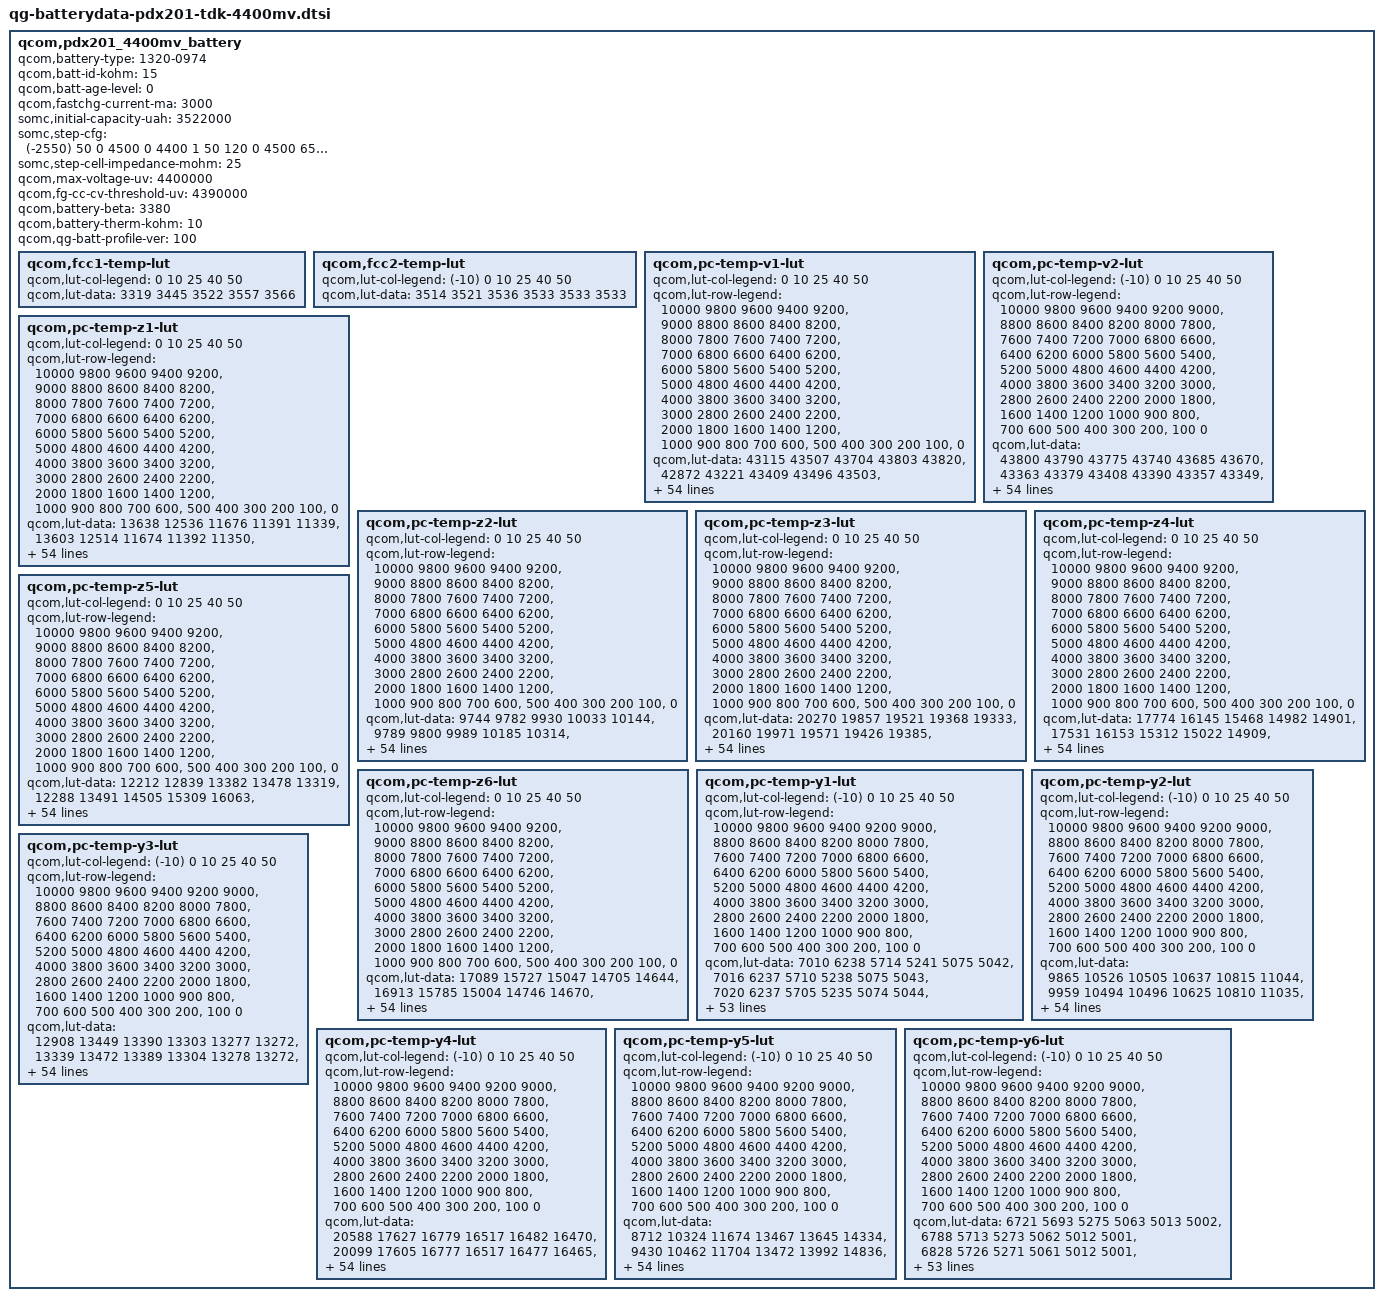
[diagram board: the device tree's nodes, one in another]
// SPDX-License-Identifier: GPL-2.0-only
/*
 * Copyright (c) 2019, The Linux Foundation. All rights reserved.
 */

qcom,pdx201_4400mv_battery {
	/* Added or Modified by SOMC */
	qcom,battery-type = "1320-0974";
	qcom,batt-id-kohm = <15>;
	qcom,batt-age-level = <0>;
	qcom,fastchg-current-ma = <3000>;
	somc,initial-capacity-uah = <3522000>;
	somc,step-cfg = <
		(-2550) 50    0 4500    0 4400 1
		   50  120    0 4500  650 4400 2
		  120  200    0 4100 2050 4400 3
		  120  200 4100 4200 1700 4400 3
		  120  200 4200 4300 1350 4400 3
		  120  200 4300 4500 1000 4400 3
		  200  450    0 4150 3000 4400 3
		  200  450 4150 4200 2550 4400 3
		  200  450 4200 4300 1700 4400 3
		  200  450 4300 4500 1000 4400 3
		  450  550    0 4500 1000 4200 4
		  550 2550    0 4500    0 4200 5
	>;
	somc,step-cell-impedance-mohm = <25>;

	/* Prepared by Qualcomm */
	/* 4176676_SoMC_Amuro2_3564mAh_averaged_MasterSlave_Sept16th2019 */
	qcom,max-voltage-uv = <4400000>;
	qcom,fg-cc-cv-threshold-uv = <4390000>;
	/* qcom,fastchg-current-ma = <1500>; */
	/* qcom,batt-id-kohm = <330>; */
	qcom,battery-beta = <3380>;
	qcom,battery-therm-kohm = <10>;
	/* qcom,battery-type = "4176676_SoMC_Amuro2_3564mAh_averaged_MasterSlave_Sept16th2019"; */
	qcom,qg-batt-profile-ver = <100>;

	qcom,fcc1-temp-lut {
		qcom,lut-col-legend = <0 10 25 40 50>;
		qcom,lut-data = <3319 3445 3522 3557 3566>;
	};

	qcom,fcc2-temp-lut {
		qcom,lut-col-legend = <(-10) 0 10 25 40 50>;
		qcom,lut-data = <3514 3521 3536 3533 3533 3533>;
	};

	qcom,pc-temp-v1-lut {
		qcom,lut-col-legend = <0 10 25 40 50>;
		qcom,lut-row-legend = <10000 9800 9600 9400 9200>,
			<9000 8800 8600 8400 8200>,
			<8000 7800 7600 7400 7200>,
			<7000 6800 6600 6400 6200>,
			<6000 5800 5600 5400 5200>,
			<5000 4800 4600 4400 4200>,
			<4000 3800 3600 3400 3200>,
			<3000 2800 2600 2400 2200>,
			<2000 1800 1600 1400 1200>,
			<1000 900 800 700 600>,
			<500 400 300 200 100>,
			<0>;
		qcom,lut-data = <43115 43507 43704 43803 43820>,
			<42872 43221 43409 43496 43503>,
			<42638 42969 43135 43212 43218>,
			<42413 42735 42882 42952 42956>,
			<42195 42504 42643 42714 42718>,
			<41984 42279 42407 42480 42488>,
			<41780 42059 42176 42246 42258>,
			<41585 41845 41951 42014 42031>,
			<41412 41638 41731 41788 41806>,
			<41248 41443 41516 41567 41580>,
			<41056 41269 41314 41350 41359>,
			<40806 41086 41131 41138 41144>,
			<40539 40857 40938 40930 40933>,
			<40297 40590 40702 40722 40728>,
			<40059 40341 40443 40506 40526>,
			<39867 40106 40226 40306 40333>,
			<39744 39902 40044 40129 40151>,
			<39648 39769 39885 39964 39978>,
			<39548 39678 39751 39808 39813>,
			<39436 39581 39630 39662 39660>,
			<39321 39455 39491 39504 39500>,
			<39205 39310 39329 39320 39315>,
			<39086 39145 39153 39125 39120>,
			<38970 38939 38945 38942 38940>,
			<38858 38753 38718 38763 38771>,
			<38748 38619 38571 38615 38624>,
			<38647 38509 38489 38508 38507>,
			<38550 38428 38423 38418 38406>,
			<38463 38369 38351 38331 38315>,
			<38395 38322 38281 38246 38231>,
			<38340 38278 38219 38172 38157>,
			<38295 38239 38163 38109 38088>,
			<38263 38202 38114 38055 38026>,
			<38237 38168 38073 38007 37974>,
			<38214 38137 38039 37967 37931>,
			<38192 38108 38005 37927 37886>,
			<38171 38083 37973 37884 37832>,
			<38137 38050 37937 37838 37771>,
			<38083 37995 37882 37776 37703>,
			<38012 37915 37801 37696 37628>,
			<37922 37825 37708 37604 37541>,
			<37804 37719 37604 37499 37433>,
			<37668 37593 37481 37377 37305>,
			<37516 37439 37325 37220 37148>,
			<37381 37290 37178 37074 37006>,
			<37288 37194 37081 36978 36915>,
			<37267 37172 37055 36955 36892>,
			<37247 37151 37038 36941 36876>,
			<37217 37131 37026 36924 36859>,
			<37145 37087 36979 36873 36800>,
			<36905 36852 36738 36612 36519>,
			<36458 36417 36309 36184 36091>,
			<35883 35850 35747 35624 35532>,
			<35120 35085 34984 34864 34773>,
			<33902 33885 33806 33695 33606>,
			<30000 30000 30000 30000 30000>;
	};

	qcom,pc-temp-v2-lut {
		qcom,lut-col-legend = <(-10) 0 10 25 40 50>;
		qcom,lut-row-legend = <10000 9800 9600 9400 9200 9000>,
			<8800 8600 8400 8200 8000 7800>,
			<7600 7400 7200 7000 6800 6600>,
			<6400 6200 6000 5800 5600 5400>,
			<5200 5000 4800 4600 4400 4200>,
			<4000 3800 3600 3400 3200 3000>,
			<2800 2600 2400 2200 2000 1800>,
			<1600 1400 1200 1000 900 800>,
			<700 600 500 400 300 200>,
			<100 0>;
		qcom,lut-data = <43800 43790 43775 43740 43685 43670>,
			<43363 43379 43408 43390 43357 43349>,
			<42985 43018 43080 43073 43055 43053>,
			<42679 42716 42797 42797 42786 42786>,
			<42438 42464 42554 42557 42546 42546>,
			<42202 42229 42324 42328 42314 42314>,
			<41913 41999 42096 42097 42083 42083>,
			<41625 41778 41875 41871 41856 41855>,
			<41448 41554 41655 41647 41632 41632>,
			<41353 41318 41432 41422 41411 41411>,
			<41247 41111 41224 41209 41195 41194>,
			<41055 40969 41055 41022 40987 40982>,
			<40781 40850 40897 40845 40783 40775>,
			<40465 40656 40684 40630 40572 40573>,
			<40028 40279 40375 40349 40344 40374>,
			<39660 39908 40079 40096 40134 40183>,
			<39512 39690 39868 39931 39972 40007>,
			<39420 39521 39690 39800 39830 39840>,
			<39300 39362 39519 39660 39681 39677>,
			<39129 39212 39359 39517 39528 39524>,
			<38923 39068 39200 39359 39361 39360>,
			<38650 38917 39029 39153 39154 39154>,
			<38310 38766 38855 38915 38921 38922>,
			<38130 38630 38702 38728 38736 38737>,
			<38075 38518 38569 38588 38592 38593>,
			<38037 38405 38451 38469 38469 38471>,
			<37994 38247 38347 38363 38362 38362>,
			<37952 38055 38253 38268 38267 38267>,
			<37910 37943 38167 38182 38181 38178>,
			<37868 37904 38090 38105 38102 38096>,
			<37826 37874 38017 38035 38031 38023>,
			<37784 37836 37937 37969 37964 37956>,
			<37744 37793 37859 37908 37904 37898>,
			<37703 37753 37803 37849 37844 37836>,
			<37664 37720 37769 37794 37787 37773>,
			<37623 37687 37736 37739 37725 37703>,
			<37577 37650 37696 37680 37643 37608>,
			<37526 37608 37651 37618 37542 37488>,
			<37468 37558 37597 37552 37451 37386>,
			<37398 37493 37530 37481 37381 37312>,
			<37319 37415 37451 37404 37311 37241>,
			<37239 37324 37356 37311 37221 37151>,
			<37158 37211 37241 37199 37110 37041>,
			<37081 37090 37103 37059 36968 36903>,
			<37007 36970 36972 36929 36846 36786>,
			<36932 36885 36899 36873 36809 36751>,
			<36887 36849 36881 36860 36797 36737>,
			<36825 36811 36858 36841 36778 36718>,
			<36761 36764 36826 36810 36743 36685>,
			<36644 36672 36748 36737 36646 36575>,
			<36395 36444 36504 36478 36345 36245>,
			<35973 36001 36024 36018 35868 35761>,
			<35363 35399 35407 35416 35249 35139>,
			<34484 34553 34572 34623 34413 34285>,
			<33079 33226 33373 33430 33159 33009>,
			<29553 29529 29520 29703 29771 29781>;
	};

	qcom,pc-temp-z1-lut {
		qcom,lut-col-legend = <0 10 25 40 50>;
		qcom,lut-row-legend = <10000 9800 9600 9400 9200>,
			<9000 8800 8600 8400 8200>,
			<8000 7800 7600 7400 7200>,
			<7000 6800 6600 6400 6200>,
			<6000 5800 5600 5400 5200>,
			<5000 4800 4600 4400 4200>,
			<4000 3800 3600 3400 3200>,
			<3000 2800 2600 2400 2200>,
			<2000 1800 1600 1400 1200>,
			<1000 900 800 700 600>,
			<500 400 300 200 100>,
			<0>;
		qcom,lut-data = <13638 12536 11676 11391 11339>,
			<13603 12514 11674 11392 11350>,
			<13593 12501 11673 11398 11352>,
			<13596 12492 11670 11399 11354>,
			<13600 12487 11667 11399 11356>,
			<13601 12483 11665 11399 11357>,
			<13603 12481 11664 11399 11357>,
			<13604 12483 11664 11399 11356>,
			<13607 12486 11665 11399 11356>,
			<13611 12487 11667 11400 11356>,
			<13607 12487 11669 11401 11357>,
			<13577 12486 11673 11403 11358>,
			<13541 12476 11676 11406 11358>,
			<13526 12452 11669 11405 11359>,
			<13516 12437 11657 11399 11359>,
			<13510 12432 11653 11395 11360>,
			<13503 12429 11653 11397 11361>,
			<13488 12432 11655 11401 11362>,
			<13485 12448 11660 11403 11363>,
			<13503 12462 11669 11404 11364>,
			<13525 12470 11675 11405 11365>,
			<13532 12476 11678 11406 11365>,
			<13529 12481 11681 11407 11366>,
			<13526 12487 11684 11408 11367>,
			<13528 12492 11687 11410 11369>,
			<13531 12494 11691 11413 11370>,
			<13535 12499 11695 11416 11372>,
			<13537 12503 11700 11419 11373>,
			<13540 12508 11704 11421 11375>,
			<13546 12513 11707 11423 11378>,
			<13559 12518 11710 11424 11380>,
			<13571 12525 11714 11427 11381>,
			<13574 12528 11718 11430 11383>,
			<13576 12530 11721 11431 11384>,
			<13579 12532 11724 11433 11385>,
			<13584 12536 11727 11434 11386>,
			<13591 12546 11730 11435 11387>,
			<13596 12553 11734 11436 11388>,
			<13603 12556 11736 11437 11389>,
			<13608 12557 11739 11438 11389>,
			<13610 12560 11740 11439 11390>,
			<13614 12566 11742 11441 11390>,
			<13601 12569 11743 11441 11391>,
			<13571 12565 11746 11441 11390>,
			<13550 12574 11750 11441 11391>,
			<13581 12571 11751 11442 11390>,
			<13550 12570 11749 11442 11391>,
			<13554 12568 11748 11442 11391>,
			<13553 12568 11745 11441 11391>,
			<13539 12573 11752 11442 11391>,
			<13560 12584 11754 11445 11393>,
			<13582 12588 11764 11448 11395>,
			<13591 12628 11778 11456 11402>,
			<13647 12665 11807 11469 11411>,
			<13647 12665 11807 11469 11411>,
			<13647 12665 11807 11469 11411>;
	};

	qcom,pc-temp-z2-lut {
		qcom,lut-col-legend = <0 10 25 40 50>;
		qcom,lut-row-legend = <10000 9800 9600 9400 9200>,
			<9000 8800 8600 8400 8200>,
			<8000 7800 7600 7400 7200>,
			<7000 6800 6600 6400 6200>,
			<6000 5800 5600 5400 5200>,
			<5000 4800 4600 4400 4200>,
			<4000 3800 3600 3400 3200>,
			<3000 2800 2600 2400 2200>,
			<2000 1800 1600 1400 1200>,
			<1000 900 800 700 600>,
			<500 400 300 200 100>,
			<0>;
		qcom,lut-data = <9744 9782 9930 10033 10144>,
			<9789 9800 9989 10185 10314>,
			<9805 9799 10014 10345 10561>,
			<9804 9797 10008 10367 10620>,
			<9802 9800 9998 10332 10602>,
			<9803 9815 9998 10311 10573>,
			<9807 9827 10007 10332 10479>,
			<9811 9831 10015 10364 10341>,
			<9815 9833 10018 10342 10309>,
			<9819 9835 10021 10219 10324>,
			<9819 9835 10025 10143 10342>,
			<9803 9836 10029 10142 10360>,
			<9785 9840 10035 10144 10379>,
			<9783 9848 10061 10156 10390>,
			<9791 9853 10099 10197 10392>,
			<9799 9856 10109 10222 10393>,
			<9806 9860 10095 10221 10405>,
			<9813 9873 10083 10219 10422>,
			<9815 9908 10106 10223 10424>,
			<9809 9942 10156 10245 10424>,
			<9801 9962 10173 10280 10426>,
			<9801 9980 10167 10371 10462>,
			<9808 9998 10162 10476 10528>,
			<9817 10021 10164 10467 10551>,
			<9825 10034 10171 10338 10552>,
			<9833 10034 10180 10257 10543>,
			<9841 10031 10192 10302 10502>,
			<9849 10028 10205 10367 10434>,
			<9856 10019 10218 10382 10381>,
			<9860 10012 10232 10381 10333>,
			<9863 10012 10236 10375 10308>,
			<9865 10015 10221 10365 10309>,
			<9867 10020 10205 10355 10317>,
			<9869 10025 10208 10363 10332>,
			<9870 10032 10222 10411 10372>,
			<9873 10038 10235 10454 10421>,
			<9878 10043 10244 10474 10480>,
			<9884 10049 10254 10492 10539>,
			<9897 10056 10269 10521 10559>,
			<9912 10065 10289 10571 10567>,
			<9926 10073 10303 10599 10574>,
			<9941 10079 10308 10543 10593>,
			<9964 10089 10313 10488 10612>,
			<10012 10110 10324 10510 10603>,
			<10241 10239 10385 10559 10625>,
			<10244 10263 10419 10555 10681>,
			<10231 10259 10407 10532 10658>,
			<10228 10265 10397 10540 10662>,
			<10234 10263 10399 10548 10671>,
			<10261 10299 10423 10642 10774>,
			<10277 10309 10486 10616 10526>,
			<10223 10256 10443 10531 10446>,
			<10136 10215 10407 10464 10375>,
			<10060 10205 10288 10383 10328>,
			<10060 10205 10288 10383 10328>,
			<10060 10205 10288 10383 10328>;
	};

	qcom,pc-temp-z3-lut {
		qcom,lut-col-legend = <0 10 25 40 50>;
		qcom,lut-row-legend = <10000 9800 9600 9400 9200>,
			<9000 8800 8600 8400 8200>,
			<8000 7800 7600 7400 7200>,
			<7000 6800 6600 6400 6200>,
			<6000 5800 5600 5400 5200>,
			<5000 4800 4600 4400 4200>,
			<4000 3800 3600 3400 3200>,
			<3000 2800 2600 2400 2200>,
			<2000 1800 1600 1400 1200>,
			<1000 900 800 700 600>,
			<500 400 300 200 100>,
			<0>;
		qcom,lut-data = <20270 19857 19521 19368 19333>,
			<20160 19971 19571 19426 19385>,
			<20084 19966 19594 19448 19409>,
			<20030 19954 19595 19449 19412>,
			<19992 19939 19595 19445 19410>,
			<19972 19913 19591 19440 19406>,
			<19959 19886 19572 19435 19394>,
			<19950 19865 19552 19428 19376>,
			<19945 19846 19537 19417 19368>,
			<19941 19827 19524 19397 19366>,
			<19940 19810 19520 19385 19363>,
			<19949 19794 19518 19385 19357>,
			<19960 19779 19517 19385 19349>,
			<19963 19759 19506 19382 19345>,
			<19957 19749 19489 19370 19344>,
			<19946 19740 19479 19363 19342>,
			<19922 19726 19460 19363 19336>,
			<19885 19705 19445 19363 19329>,
			<19871 19667 19438 19362 19327>,
			<19898 19647 19430 19355 19327>,
			<19939 19652 19435 19351 19328>,
			<19966 19663 19466 19368 19336>,
			<19986 19683 19495 19393 19352>,
			<20001 19734 19505 19393 19352>,
			<20011 19772 19512 19371 19332>,
			<20019 19771 19512 19357 19318>,
			<20025 19765 19497 19361 19335>,
			<20029 19758 19481 19370 19365>,
			<20032 19744 19485 19383 19371>,
			<20032 19728 19499 19407 19370>,
			<20024 19717 19509 19420 19368>,
			<20013 19708 19515 19417 19367>,
			<20001 19704 19519 19409 19365>,
			<19985 19705 19518 19404 19362>,
			<19971 19705 19511 19399 19355>,
			<19959 19705 19505 19395 19351>,
			<19949 19702 19501 19390 19352>,
			<19938 19699 19497 19386 19353>,
			<19929 19694 19493 19384 19353>,
			<19918 19688 19489 19384 19348>,
			<19904 19681 19484 19382 19345>,
			<19886 19672 19478 19375 19346>,
			<19863 19659 19471 19365 19346>,
			<19828 19641 19464 19361 19346>,
			<19688 19580 19442 19356 19338>,
			<19681 19568 19434 19355 19331>,
			<19671 19557 19435 19353 19329>,
			<19663 19554 19432 19345 19327>,
			<19662 19551 19416 19344 19324>,
			<19655 19537 19415 19334 19320>,
			<19643 19542 19405 19343 19344>,
			<19641 19535 19403 19348 19349>,
			<19635 19530 19405 19356 19353>,
			<19571 19481 19391 19359 19357>,
			<19571 19481 19391 19359 19357>,
			<19571 19481 19391 19359 19357>;
	};

	qcom,pc-temp-z4-lut {
		qcom,lut-col-legend = <0 10 25 40 50>;
		qcom,lut-row-legend = <10000 9800 9600 9400 9200>,
			<9000 8800 8600 8400 8200>,
			<8000 7800 7600 7400 7200>,
			<7000 6800 6600 6400 6200>,
			<6000 5800 5600 5400 5200>,
			<5000 4800 4600 4400 4200>,
			<4000 3800 3600 3400 3200>,
			<3000 2800 2600 2400 2200>,
			<2000 1800 1600 1400 1200>,
			<1000 900 800 700 600>,
			<500 400 300 200 100>,
			<0>;
		qcom,lut-data = <17774 16145 15468 14982 14901>,
			<17531 16153 15312 15022 14909>,
			<17261 15934 15185 14962 14875>,
			<16942 15611 15084 14913 14840>,
			<16635 15427 15002 14872 14803>,
			<16405 15307 14943 14840 14782>,
			<16217 15215 14895 14815 14782>,
			<16060 15144 14865 14797 14783>,
			<15930 15087 14853 14795 14781>,
			<15820 15037 14844 14796 14772>,
			<15721 14986 14833 14796 14761>,
			<15632 14951 14818 14792 14755>,
			<15553 14938 14807 14783 14749>,
			<15481 14930 14804 14775 14741>,
			<15415 14924 14803 14767 14730>,
			<15359 14913 14799 14757 14719>,
			<15317 14902 14791 14737 14711>,
			<15282 14895 14786 14715 14704>,
			<15241 14891 14783 14705 14696>,
			<15181 14886 14774 14700 14684>,
			<15120 14876 14764 14698 14677>,
			<15079 14865 14747 14706 14691>,
			<15046 14865 14735 14726 14722>,
			<15027 14886 14775 14761 14760>,
			<15024 14911 14867 14834 14819>,
			<15023 14933 14900 14875 14852>,
			<15023 14956 14894 14860 14827>,
			<15030 14964 14882 14831 14779>,
			<15040 14959 14862 14799 14752>,
			<15045 14952 14831 14757 14736>,
			<15048 14944 14806 14729 14723>,
			<15050 14935 14787 14720 14709>,
			<15049 14925 14773 14714 14698>,
			<15044 14912 14768 14709 14693>,
			<15039 14900 14766 14704 14689>,
			<15031 14894 14765 14702 14687>,
			<15023 14890 14767 14708 14698>,
			<15014 14888 14770 14720 14716>,
			<15004 14893 14778 14729 14720>,
			<14997 14902 14795 14737 14721>,
			<14996 14905 14803 14741 14721>,
			<14995 14899 14796 14739 14713>,
			<14987 14891 14790 14738 14705>,
			<14950 14875 14789 14743 14709>,
			<14868 14815 14768 14735 14710>,
			<14858 14799 14744 14719 14703>,
			<14855 14795 14731 14709 14691>,
			<14847 14785 14726 14696 14673>,
			<14830 14778 14724 14680 14656>,
			<14826 14776 14724 14693 14665>,
			<14841 14788 14754 14709 14664>,
			<14858 14798 14758 14706 14661>,
			<14865 14799 14752 14696 14656>,
			<14920 14830 14761 14689 14651>,
			<14920 14830 14761 14689 14651>,
			<14920 14830 14761 14689 14651>;
	};

	qcom,pc-temp-z5-lut {
		qcom,lut-col-legend = <0 10 25 40 50>;
		qcom,lut-row-legend = <10000 9800 9600 9400 9200>,
			<9000 8800 8600 8400 8200>,
			<8000 7800 7600 7400 7200>,
			<7000 6800 6600 6400 6200>,
			<6000 5800 5600 5400 5200>,
			<5000 4800 4600 4400 4200>,
			<4000 3800 3600 3400 3200>,
			<3000 2800 2600 2400 2200>,
			<2000 1800 1600 1400 1200>,
			<1000 900 800 700 600>,
			<500 400 300 200 100>,
			<0>;
		qcom,lut-data = <12212 12839 13382 13478 13319>,
			<12288 13491 14505 15309 16063>,
			<12396 13827 15287 16459 17601>,
			<12566 14071 15774 16701 18276>,
			<12748 14279 16142 16721 18737>,
			<12882 14456 16415 16778 18954>,
			<12994 14624 16651 17133 18202>,
			<13086 14780 16755 17580 16836>,
			<13149 14942 16622 17409 16524>,
			<13202 15195 16409 16309 16718>,
			<13282 15674 16442 15644 16854>,
			<13465 16095 16965 15833 16639>,
			<13664 16331 17365 16123 16269>,
			<13767 16647 17061 16086 16254>,
			<13852 16805 16538 15656 16706>,
			<13866 16818 16372 15402 17036>,
			<13748 16751 16061 16240 16953>,
			<13566 16454 15691 17494 16800>,
			<13510 15842 15454 17731 16863>,
			<14112 15504 15278 17561 17627>,
			<15180 16044 16150 17511 18887>,
			<16276 17434 21145 23134 22353>,
			<17587 20253 25668 31425 26987>,
			<18974 28450 26495 31127 26841>,
			<20340 34642 26956 22317 19534>,
			<21727 33528 26771 16323 14305>,
			<22963 30211 22446 15602 14942>,
			<24248 27363 18175 15220 16287>,
			<25257 24760 18075 15724 17193>,
			<25384 22667 18697 18648 17768>,
			<24964 21742 19524 21357 18479>,
			<24382 21127 21382 22640 19915>,
			<23668 20908 23305 23673 21723>,
			<22701 21354 24074 24957 23073>,
			<22083 22091 24557 26586 24329>,
			<21805 22554 24705 27384 24959>,
			<21624 22916 24497 26376 24639>,
			<21665 23096 24075 24462 23841>,
			<22258 23045 23351 22956 22659>,
			<22827 22889 22014 21582 20402>,
			<22856 22624 20913 20237 19067>,
			<22759 21923 20274 18876 19090>,
			<23105 21485 19695 17654 19118>,
			<24125 21317 18941 16539 18333>,
			<24632 23018 19280 16681 16856>,
			<24827 23491 20029 17280 16399>,
			<23314 22244 20498 17378 16692>,
			<22782 22442 20481 17230 17704>,
			<23778 22553 18760 18126 19333>,
			<24028 21583 19227 16420 17540>,
			<22492 21657 16416 15154 18371>,
			<19474 19030 15759 15249 19007>,
			<17856 17760 15636 15906 20142>,
			<14403 14565 14559 16398 21340>,
			<14403 14565 14559 16398 21340>,
			<14403 14565 14559 16398 21340>;
	};

	qcom,pc-temp-z6-lut {
		qcom,lut-col-legend = <0 10 25 40 50>;
		qcom,lut-row-legend = <10000 9800 9600 9400 9200>,
			<9000 8800 8600 8400 8200>,
			<8000 7800 7600 7400 7200>,
			<7000 6800 6600 6400 6200>,
			<6000 5800 5600 5400 5200>,
			<5000 4800 4600 4400 4200>,
			<4000 3800 3600 3400 3200>,
			<3000 2800 2600 2400 2200>,
			<2000 1800 1600 1400 1200>,
			<1000 900 800 700 600>,
			<500 400 300 200 100>,
			<0>;
		qcom,lut-data = <17089 15727 15047 14705 14644>,
			<16913 15785 15004 14746 14670>,
			<16743 15689 14964 14737 14670>,
			<16566 15533 14924 14725 14667>,
			<16408 15437 14887 14704 14651>,
			<16293 15369 14855 14686 14636>,
			<16201 15314 14825 14673 14626>,
			<16126 15270 14803 14662 14619>,
			<16065 15234 14789 14652 14613>,
			<16012 15202 14779 14643 14607>,
			<15964 15174 14771 14636 14601>,
			<15921 15150 14766 14633 14595>,
			<15881 15130 14760 14631 14589>,
			<15843 15113 14751 14626 14583>,
			<15804 15099 14740 14615 14577>,
			<15768 15087 14730 14605 14571>,
			<15734 15076 14718 14596 14564>,
			<15701 15061 14707 14588 14558>,
			<15686 15043 14700 14581 14552>,
			<15681 15034 14694 14575 14547>,
			<15678 15035 14693 14573 14544>,
			<15677 15037 14700 14584 14554>,
			<15678 15045 14713 14605 14576>,
			<15679 15081 14740 14624 14593>,
			<15682 15115 14781 14644 14608>,
			<15688 15125 14795 14653 14616>,
			<15694 15132 14785 14649 14614>,
			<15701 15134 14773 14642 14609>,
			<15707 15126 14766 14636 14603>,
			<15708 15114 14761 14631 14595>,
			<15708 15106 14756 14626 14588>,
			<15706 15099 14752 14619 14581>,
			<15701 15094 14748 14613 14576>,
			<15691 15089 14744 14607 14570>,
			<15682 15085 14740 14602 14565>,
			<15675 15083 14738 14599 14562>,
			<15668 15082 14737 14600 14567>,
			<15662 15081 14736 14602 14574>,
			<15655 15082 14737 14605 14576>,
			<15649 15083 14742 14608 14574>,
			<15643 15083 14744 14609 14572>,
			<15637 15078 14739 14604 14569>,
			<15622 15070 14733 14599 14566>,
			<15585 15056 14729 14599 14568>,
			<15482 15002 14709 14593 14564>,
			<15473 14991 14694 14585 14557>,
			<15465 14982 14689 14580 14551>,
			<15453 14974 14685 14570 14542>,
			<15448 14969 14675 14562 14533>,
			<15448 14964 14676 14562 14534>,
			<15458 14977 14684 14575 14547>,
			<15478 14984 14688 14577 14550>,
			<15497 14994 14689 14579 14551>,
			<15521 15002 14693 14580 14553>,
			<15521 15002 14693 14580 14553>,
			<15521 15002 14693 14580 14553>;
	};

	qcom,pc-temp-y1-lut {
		qcom,lut-col-legend = <(-10) 0 10 25 40 50>;
		qcom,lut-row-legend = <10000 9800 9600 9400 9200 9000>,
			<8800 8600 8400 8200 8000 7800>,
			<7600 7400 7200 7000 6800 6600>,
			<6400 6200 6000 5800 5600 5400>,
			<5200 5000 4800 4600 4400 4200>,
			<4000 3800 3600 3400 3200 3000>,
			<2800 2600 2400 2200 2000 1800>,
			<1600 1400 1200 1000 900 800>,
			<700 600 500 400 300 200>,
			<100 0>;
		qcom,lut-data = <7010 6238 5714 5241 5075 5042>,
			<7016 6237 5710 5238 5075 5043>,
			<7020 6237 5705 5235 5074 5044>,
			<7022 6237 5701 5231 5074 5045>,
			<7023 6237 5697 5229 5074 5045>,
			<7023 6238 5695 5227 5073 5045>,
			<7021 6241 5694 5226 5073 5045>,
			<7018 6245 5693 5225 5073 5044>,
			<7017 6245 5690 5224 5072 5044>,
			<7016 6239 5682 5224 5071 5044>,
			<7015 6234 5677 5223 5071 5045>,
			<7016 6237 5677 5222 5070 5044>,
			<7017 6244 5677 5220 5070 5044>,
			<7016 6246 5677 5219 5071 5044>,
			<7010 6247 5674 5220 5071 5044>,
			<7004 6247 5673 5221 5071 5045>,
			<7005 6249 5675 5224 5072 5046>,
			<7008 6255 5680 5227 5072 5046>,
			<7009 6257 5682 5228 5072 5047>,
			<7008 6257 5678 5228 5073 5048>,
			<7007 6258 5675 5228 5074 5048>,
			<7015 6266 5677 5229 5075 5049>,
			<7037 6286 5683 5230 5076 5049>,
			<7046 6294 5687 5232 5076 5049>,
			<7034 6284 5690 5235 5077 5049>,
			<7019 6272 5691 5238 5078 5050>,
			<7009 6270 5695 5242 5079 5050>,
			<6994 6268 5699 5247 5081 5051>,
			<6987 6269 5700 5252 5083 5052>,
			<7003 6282 5702 5257 5083 5053>,
			<7025 6298 5704 5262 5084 5054>,
			<7021 6296 5709 5265 5085 5055>,
			<6994 6284 5718 5268 5089 5057>,
			<6977 6278 5724 5272 5091 5059>,
			<6985 6282 5728 5277 5093 5060>,
			<6998 6288 5731 5281 5094 5061>,
			<6998 6349 5736 5285 5096 5062>,
			<6992 6563 5744 5288 5098 5063>,
			<6986 6672 5750 5291 5099 5063>,
			<6981 6519 5758 5292 5099 5064>,
			<6982 6317 5766 5294 5100 5064>,
			<6997 6284 5764 5295 5100 5064>,
			<7032 6297 5757 5297 5100 5064>,
			<7031 6299 5761 5300 5101 5065>,
			<6977 6288 5771 5303 5102 5066>,
			<6983 6282 5768 5305 5101 5067>,
			<6972 6299 5762 5303 5103 5066>,
			<6994 6286 5773 5304 5104 5067>,
			<7011 6290 5769 5304 5103 5067>,
			<7022 6299 5774 5310 5103 5065>,
			<7036 6299 5782 5310 5104 5068>,
			<7046 6336 5785 5322 5108 5072>,
			<7118 6349 5816 5336 5114 5076>,
			<7198 6375 5835 5352 5121 5080>,
			<7198 6375 5835 5352 5121 5080>,
			<7198 6375 5835 5352 5121 5080>;
	};

	qcom,pc-temp-y2-lut {
		qcom,lut-col-legend = <(-10) 0 10 25 40 50>;
		qcom,lut-row-legend = <10000 9800 9600 9400 9200 9000>,
			<8800 8600 8400 8200 8000 7800>,
			<7600 7400 7200 7000 6800 6600>,
			<6400 6200 6000 5800 5600 5400>,
			<5200 5000 4800 4600 4400 4200>,
			<4000 3800 3600 3400 3200 3000>,
			<2800 2600 2400 2200 2000 1800>,
			<1600 1400 1200 1000 900 800>,
			<700 600 500 400 300 200>,
			<100 0>;
		qcom,lut-data = <9865 10526 10505 10637 10815 11044>,
			<9959 10494 10496 10625 10810 11035>,
			<10083 10460 10487 10618 10801 11027>,
			<10214 10426 10478 10614 10791 11019>,
			<10329 10396 10467 10614 10783 11013>,
			<10405 10375 10457 10617 10779 11011>,
			<10456 10359 10444 10625 10779 10997>,
			<10498 10347 10431 10636 10778 10971>,
			<10489 10344 10426 10639 10780 10967>,
			<10371 10353 10423 10638 10795 10983>,
			<10276 10371 10420 10636 10806 10996>,
			<10394 10429 10417 10631 10805 10978>,
			<10644 10522 10415 10627 10803 10943>,
			<10722 10546 10421 10631 10804 10941>,
			<10701 10517 10479 10677 10810 11004>,
			<10664 10492 10538 10726 10823 11055>,
			<10587 10522 10564 10749 10852 11034>,
			<10435 10600 10583 10765 10902 10988>,
			<10254 10657 10606 10788 10952 10982>,
			<9973 10690 10635 10823 11013 11056>,
			<9742 10720 10666 10849 11052 11121>,
			<9695 10758 10697 10853 11033 11115>,
			<9674 10798 10730 10856 10992 11093>,
			<9664 10808 10764 10863 10981 11090>,
			<9659 10730 10798 10902 11009 11100>,
			<9656 10632 10833 10953 11048 11114>,
			<9655 10583 10873 10996 11081 11142>,
			<9654 10551 10912 11043 11115 11186>,
			<9654 10544 10924 11079 11155 11230>,
			<9654 10569 10923 11106 11213 11275>,
			<9654 10577 10921 11132 11264 11321>,
			<9654 10430 10919 11163 11279 11361>,
			<9653 10023 10912 11196 11280 11399>,
			<9653 9779 10897 11208 11297 11445>,
			<9653 9723 10823 11206 11406 11542>,
			<9653 9691 10731 11202 11516 11622>,
			<9653 9684 10674 11187 11501 11619>,
			<9653 9687 10629 11149 11427 11591>,
			<9653 9688 10590 11120 11395 11574>,
			<9653 9677 10556 11106 11422 11584>,
			<9653 9664 10524 11093 11454 11600>,
			<9653 9660 10490 11067 11442 11598>,
			<9653 9659 10455 11028 11398 11573>,
			<9653 9657 10423 11004 11392 11592>,
			<9653 9655 10390 10976 11384 11630>,
			<9652 9654 10372 10937 11291 11432>,
			<9652 9655 10397 10954 11338 11402>,
			<9652 9655 10376 10955 11342 11358>,
			<9652 9654 10357 10947 11273 11255>,
			<9652 9654 10338 10933 11178 11180>,
			<9652 9653 10318 10900 11217 11153>,
			<9651 9653 10263 10850 11162 11119>,
			<9650 9652 10208 10792 11084 11033>,
			<9649 9651 10159 10708 10964 10909>,
			<9649 9651 10159 10708 10964 10909>,
			<9649 9651 10159 10708 10964 10909>;
	};

	qcom,pc-temp-y3-lut {
		qcom,lut-col-legend = <(-10) 0 10 25 40 50>;
		qcom,lut-row-legend = <10000 9800 9600 9400 9200 9000>,
			<8800 8600 8400 8200 8000 7800>,
			<7600 7400 7200 7000 6800 6600>,
			<6400 6200 6000 5800 5600 5400>,
			<5200 5000 4800 4600 4400 4200>,
			<4000 3800 3600 3400 3200 3000>,
			<2800 2600 2400 2200 2000 1800>,
			<1600 1400 1200 1000 900 800>,
			<700 600 500 400 300 200>,
			<100 0>;
		qcom,lut-data = <12908 13449 13390 13303 13277 13272>,
			<13339 13472 13389 13304 13278 13272>,
			<13613 13496 13390 13306 13279 13273>,
			<13764 13517 13391 13307 13280 13274>,
			<13830 13532 13392 13308 13281 13275>,
			<13844 13538 13392 13308 13282 13276>,
			<13744 13534 13396 13308 13282 13277>,
			<13562 13526 13400 13308 13283 13278>,
			<13516 13528 13402 13308 13283 13278>,
			<13537 13558 13404 13307 13283 13278>,
			<13571 13582 13407 13306 13282 13278>,
			<13643 13573 13413 13310 13284 13278>,
			<13747 13552 13419 13316 13288 13278>,
			<13766 13535 13420 13318 13289 13278>,
			<13640 13519 13412 13316 13288 13277>,
			<13512 13501 13406 13314 13288 13276>,
			<13478 13483 13407 13317 13289 13277>,
			<13459 13466 13410 13324 13291 13279>,
			<13456 13455 13410 13327 13293 13282>,
			<13485 13450 13402 13329 13295 13284>,
			<13514 13444 13391 13329 13296 13285>,
			<13509 13436 13381 13325 13294 13283>,
			<13492 13424 13371 13314 13288 13278>,
			<13488 13410 13362 13307 13285 13276>,
			<13591 13392 13353 13302 13282 13276>,
			<13752 13375 13348 13299 13281 13276>,
			<13878 13362 13347 13298 13281 13276>,
			<13997 13350 13347 13297 13281 13276>,
			<14096 13347 13346 13297 13281 13276>,
			<14171 13374 13343 13300 13283 13276>,
			<14235 13406 13340 13303 13284 13275>,
			<14295 13406 13338 13303 13284 13275>,
			<14349 13396 13337 13301 13283 13277>,
			<14404 13391 13338 13300 13283 13278>,
			<14460 13406 13347 13300 13283 13277>,
			<14517 13430 13359 13300 13283 13277>,
			<14574 13449 13367 13301 13282 13276>,
			<14630 13464 13374 13302 13279 13273>,
			<14687 13485 13378 13303 13277 13272>,
			<14745 13524 13382 13303 13278 13272>,
			<14805 13579 13384 13302 13280 13273>,
			<14874 13641 13387 13303 13280 13273>,
			<14955 13718 13390 13305 13281 13274>,
			<15049 13817 13394 13306 13279 13273>,
			<15159 13949 13400 13308 13277 13273>,
			<15300 14102 13401 13310 13284 13275>,
			<15144 13959 13396 13308 13284 13276>,
			<15197 14042 13403 13308 13287 13280>,
			<15379 14188 13413 13309 13289 13286>,
			<15553 14326 13426 13317 13290 13284>,
			<15717 14478 13433 13314 13291 13282>,
			<16136 14692 13433 13322 13292 13284>,
			<16843 15117 13463 13326 13294 13288>,
			<17716 15649 13504 13339 13297 13289>,
			<17716 15649 13504 13339 13297 13289>,
			<17716 15649 13504 13339 13297 13289>;
	};

	qcom,pc-temp-y4-lut {
		qcom,lut-col-legend = <(-10) 0 10 25 40 50>;
		qcom,lut-row-legend = <10000 9800 9600 9400 9200 9000>,
			<8800 8600 8400 8200 8000 7800>,
			<7600 7400 7200 7000 6800 6600>,
			<6400 6200 6000 5800 5600 5400>,
			<5200 5000 4800 4600 4400 4200>,
			<4000 3800 3600 3400 3200 3000>,
			<2800 2600 2400 2200 2000 1800>,
			<1600 1400 1200 1000 900 800>,
			<700 600 500 400 300 200>,
			<100 0>;
		qcom,lut-data = <20588 17627 16779 16517 16482 16470>,
			<20099 17605 16777 16517 16477 16465>,
			<19763 17585 16775 16517 16474 16462>,
			<19555 17567 16773 16517 16473 16460>,
			<19448 17554 16773 16517 16473 16458>,
			<19416 17546 16773 16517 16473 16458>,
			<19515 17545 16769 16519 16474 16458>,
			<19708 17547 16764 16526 16478 16460>,
			<19798 17535 16764 16533 16482 16462>,
			<19841 17471 16770 16544 16490 16466>,
			<19861 17421 16780 16556 16496 16471>,
			<19635 17544 16812 16570 16501 16477>,
			<19104 17791 16858 16583 16505 16484>,
			<18744 17836 16867 16589 16510 16491>,
			<18491 17561 16857 16593 16519 16500>,
			<18346 17322 16850 16598 16529 16509>,
			<18359 17338 16858 16621 16541 16517>,
			<18405 17394 16873 16664 16556 16525>,
			<18412 17411 16875 16698 16576 16537>,
			<18233 17389 16849 16729 16608 16559>,
			<17952 17355 16814 16747 16630 16575>,
			<17625 17316 16774 16697 16602 16556>,
			<17223 17269 16732 16584 16533 16509>,
			<17073 17228 16719 16537 16497 16483>,
			<17091 17202 16717 16527 16481 16469>,
			<17116 17170 16716 16522 16473 16462>,
			<17130 17063 16718 16525 16474 16463>,
			<17141 16852 16723 16534 16478 16465>,
			<17151 16762 16724 16542 16483 16468>,
			<17162 16777 16721 16547 16489 16475>,
			<17174 16806 16715 16553 16497 16485>,
			<17190 16859 16692 16564 16509 16497>,
			<17213 16959 16646 16580 16524 16509>,
			<17228 17033 16631 16585 16534 16515>,
			<17234 17070 16661 16579 16540 16516>,
			<17238 17098 16700 16571 16543 16515>,
			<17239 17117 16725 16566 16533 16507>,
			<17238 17133 16745 16560 16504 16484>,
			<17237 17146 16762 16558 16491 16474>,
			<17226 17160 16774 16559 16495 16478>,
			<17209 17171 16785 16559 16499 16482>,
			<17206 17171 16798 16561 16500 16482>,
			<17212 17162 16812 16564 16499 16480>,
			<17227 17155 16824 16565 16497 16477>,
			<17276 17153 16834 16564 16493 16472>,
			<17400 17182 16831 16567 16498 16482>,
			<17320 17144 16793 16564 16506 16489>,
			<17325 17206 16822 16582 16512 16493>,
			<17376 17283 16878 16607 16523 16502>,
			<17402 17337 16931 16615 16531 16513>,
			<17381 17355 16933 16597 16500 16478>,
			<17489 17334 16924 16601 16505 16483>,
			<17800 17362 16988 16635 16525 16507>,
			<18417 17730 17086 16729 16594 16559>,
			<18417 17730 17086 16729 16594 16559>,
			<18417 17730 17086 16729 16594 16559>;
	};

	qcom,pc-temp-y5-lut {
		qcom,lut-col-legend = <(-10) 0 10 25 40 50>;
		qcom,lut-row-legend = <10000 9800 9600 9400 9200 9000>,
			<8800 8600 8400 8200 8000 7800>,
			<7600 7400 7200 7000 6800 6600>,
			<6400 6200 6000 5800 5600 5400>,
			<5200 5000 4800 4600 4400 4200>,
			<4000 3800 3600 3400 3200 3000>,
			<2800 2600 2400 2200 2000 1800>,
			<1600 1400 1200 1000 900 800>,
			<700 600 500 400 300 200>,
			<100 0>;
		qcom,lut-data = <8712 10324 11674 13467 13645 14334>,
			<9430 10462 11704 13472 13992 14836>,
			<10248 10626 11736 13475 14200 15217>,
			<10810 10791 11768 13477 14304 15483>,
			<11139 10931 11797 13476 14337 15640>,
			<11253 11023 11821 13475 14330 15694>,
			<11016 11068 11940 13376 14221 15626>,
			<10585 11101 12122 13148 13984 15454>,
			<10505 11134 12174 12888 13700 15227>,
			<10847 11131 12249 12513 13264 14847>,
			<11413 11149 12283 12286 12996 14428>,
			<12683 11372 12187 12395 13251 14034>,
			<14507 11808 12063 12615 13733 13628>,
			<14907 12196 12099 12700 13805 13233>,
			<13412 12715 12652 12661 13359 12785>,
			<12049 13070 13320 12637 12998 12524>,
			<12297 12852 13869 12770 13032 12634>,
			<13232 12331 14368 13094 13157 12928>,
			<14219 12175 14555 13612 13332 13220>,
			<15472 12495 14635 14884 13658 13512>,
			<16392 12922 14677 15959 14109 13849>,
			<15341 13188 14528 15962 14866 14280>,
			<12197 13412 14145 15507 15822 14806>,
			<10837 13779 13813 15217 16062 15340>,
			<10892 14762 13481 14442 15557 15984>,
			<10970 15629 13272 13711 14992 16409>,
			<11030 14987 13391 13483 14746 16342>,
			<11125 12929 13799 13206 14574 16061>,
			<11193 12039 14394 13149 14551 15688>,
			<11235 12490 15724 13781 14861 14975>,
			<11269 12993 16793 14545 15164 14403>,
			<11284 12750 16542 14846 15104 14491>,
			<11289 11735 15769 15026 14893 14894>,
			<11304 11213 15418 15310 14858 15287>,
			<11413 11251 15363 16026 15873 15700>,
			<11562 11316 15317 16648 16954 15995>,
			<11639 11397 15158 16676 16640 15882>,
			<11729 11541 14838 16583 15433 15412>,
			<11781 11613 14531 16440 14897 15013>,
			<11726 11567 14138 15879 15036 14719>,
			<11608 11510 13710 15298 15198 14507>,
			<11502 11497 13362 15130 15192 14448>,
			<11376 11458 13035 15005 15074 14435>,
			<11322 11425 12817 15003 14619 14519>,
			<11304 11367 12690 15039 14175 14785>,
			<11144 11271 12711 15086 15352 14222>,
			<11360 11311 13083 15121 14779 13680>,
			<11390 11173 12956 14308 14714 14271>,
			<11637 11286 12826 13677 14612 16285>,
			<11961 11526 12944 14380 14830 15404>,
			<11880 11612 13161 14545 16859 16199>,
			<11190 11354 12892 15825 17550 17225>,
			<10527 11356 12970 15704 17565 18899>,
			<10109 10723 13313 16396 17527 17730>,
			<10109 10723 13313 16396 17527 17730>,
			<10109 10723 13313 16396 17527 17730>;
	};

	qcom,pc-temp-y6-lut {
		qcom,lut-col-legend = <(-10) 0 10 25 40 50>;
		qcom,lut-row-legend = <10000 9800 9600 9400 9200 9000>,
			<8800 8600 8400 8200 8000 7800>,
			<7600 7400 7200 7000 6800 6600>,
			<6400 6200 6000 5800 5600 5400>,
			<5200 5000 4800 4600 4400 4200>,
			<4000 3800 3600 3400 3200 3000>,
			<2800 2600 2400 2200 2000 1800>,
			<1600 1400 1200 1000 900 800>,
			<700 600 500 400 300 200>,
			<100 0>;
		qcom,lut-data = <6721 5693 5275 5063 5013 5002>,
			<6788 5713 5273 5062 5012 5001>,
			<6828 5726 5271 5061 5012 5001>,
			<6849 5734 5270 5061 5012 5001>,
			<6857 5737 5270 5062 5013 5001>,
			<6859 5738 5269 5062 5014 5002>,
			<6825 5734 5269 5064 5015 5003>,
			<6764 5726 5270 5065 5016 5003>,
			<6753 5722 5270 5067 5017 5005>,
			<6789 5721 5273 5069 5019 5006>,
			<6819 5721 5276 5072 5021 5008>,
			<6799 5748 5288 5079 5024 5009>,
			<6741 5803 5305 5087 5027 5011>,
			<6666 5809 5308 5089 5030 5013>,
			<6521 5719 5298 5089 5032 5015>,
			<6411 5640 5291 5089 5034 5017>,
			<6419 5639 5294 5097 5038 5020>,
			<6451 5644 5301 5115 5044 5024>,
			<6461 5645 5301 5127 5051 5029>,
			<6441 5637 5288 5136 5061 5037>,
			<6405 5625 5270 5141 5068 5042>,
			<6350 5611 5253 5124 5058 5035>,
			<6270 5593 5235 5084 5034 5017>,
			<6243 5577 5224 5065 5021 5008>,
			<6375 5565 5219 5059 5015 5004>,
			<6568 5551 5216 5056 5012 5002>,
			<6690 5519 5217 5057 5012 5002>,
			<6787 5469 5220 5059 5013 5003>,
			<6865 5450 5221 5062 5015 5004>,
			<6924 5506 5220 5066 5017 5006>,
			<6974 5594 5218 5070 5021 5008>,
			<7021 5659 5212 5074 5024 5011>,
			<7064 5717 5203 5077 5028 5016>,
			<7105 5771 5201 5078 5030 5018>,
			<7146 5821 5221 5077 5033 5018>,
			<7186 5869 5249 5076 5034 5018>,
			<7228 5919 5268 5075 5030 5015>,
			<7271 5970 5286 5075 5019 5006>,
			<7313 6024 5301 5075 5015 5003>,
			<7354 6082 5314 5076 5017 5004>,
			<7396 6144 5327 5077 5020 5006>,
			<7447 6214 5343 5078 5020 5006>,
			<7510 6295 5361 5080 5020 5006>,
			<7588 6390 5383 5082 5019 5005>,
			<7687 6505 5409 5084 5016 5003>,
			<7816 6640 5413 5087 5022 5008>,
			<7692 6513 5376 5084 5025 5011>,
			<7739 6598 5402 5090 5028 5014>,
			<7884 6735 5440 5098 5033 5022>,
			<8023 6859 5481 5107 5036 5023>,
			<8147 6985 5504 5100 5028 5012>,
			<8536 7152 5528 5108 5031 5015>,
			<9228 7489 5632 5124 5039 5025>,
			<10092 8056 5762 5163 5062 5042>,
			<10092 8056 5762 5163 5062 5042>,
			<10092 8056 5762 5163 5062 5042>;
	};

};
